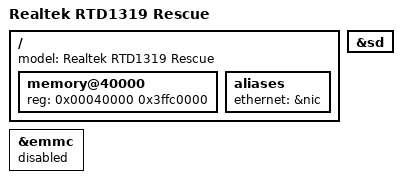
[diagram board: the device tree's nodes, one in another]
// SPDX-License-Identifier: (GPL-2.0-or-later OR BSD-2-Clause)
/*
 * Copyright (c) 2019 Realtek Semiconductor Corp.
 */

/dts-v1/;

#include "rtd13xx-rescue.dtsi"

/ {
	model = "Realtek RTD1319 Rescue";

	memory@40000 {
		device_type = "memory";
		reg = <0x00040000 0x3ffc0000>; /* 1 GiB */
	};

	aliases {
		ethernet = &nic;
	};
};

&sd {
	status = "okay";
};

&emmc {
	status = "disabled";
};
